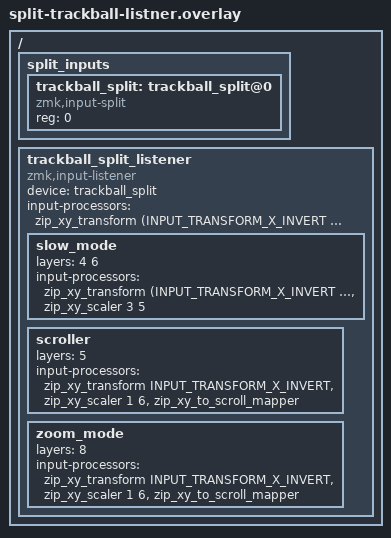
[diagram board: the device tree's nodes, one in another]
#include <input/processors.dtsi>
#include <dt-bindings/zmk/input_transform.h>

/{
    split_inputs {
        #address-cells = <1>;
        #size-cells = <0>;

        trackball_split: trackball_split@0 {
            compatible = "zmk,input-split";
            reg = <0>;
        };
    };

    trackball_split_listener: trackball_split_listener {
        compatible = "zmk,input-listener";
        device = <&trackball_split>;
        status = "okay";

        // Default: mouse movement mode
        input-processors = <
            &zip_xy_transform (INPUT_TRANSFORM_X_INVERT | INPUT_TRANSFORM_Y_INVERT)
        >;

        // When layer 4 (MOUSE) or layer 6 (CMD_SLOW) is active: slow mode for precise selection
        slow_mode {
            layers = <4 6>;
            input-processors = <
                &zip_xy_transform (INPUT_TRANSFORM_X_INVERT | INPUT_TRANSFORM_Y_INVERT)
                &zip_xy_scaler 3 5
            >;
        };

        // When layer 5 is active: scroll mode
        scroller {
            layers = <5>;
            input-processors = <
                &zip_xy_transform INPUT_TRANSFORM_X_INVERT
                &zip_xy_scaler 1 6
                &zip_xy_to_scroll_mapper
            >;
        };

        // When layer 8 (ZOOM) is active: Cmd+scroll for zoom in Figma etc.
        zoom_mode {
            layers = <8>;
            input-processors = <
                &zip_xy_transform INPUT_TRANSFORM_X_INVERT
                &zip_xy_scaler 1 6
                &zip_xy_to_scroll_mapper
            >;
        };
     };
};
